# IPU2_UNICACHE_SCTM register map
Vendor: Texas Instruments
Peripheral module from a debugger description file (folder DRA74xP_75xP_76xP_77xP).
Registers are 32-bit, access per field, reset 0x0 unless marked. A register's access mark holds for its fields unless they carry their own. Offsets are as the file gives them; lines under a group give offsets from that group; [hi:lo] are bit positions; {n}, {i} and the like mark numbered series; 'fields as' and 'values as' point back to an identical list; <NAME> marks a mode.

## IPU2_UNICACHE_SCTM
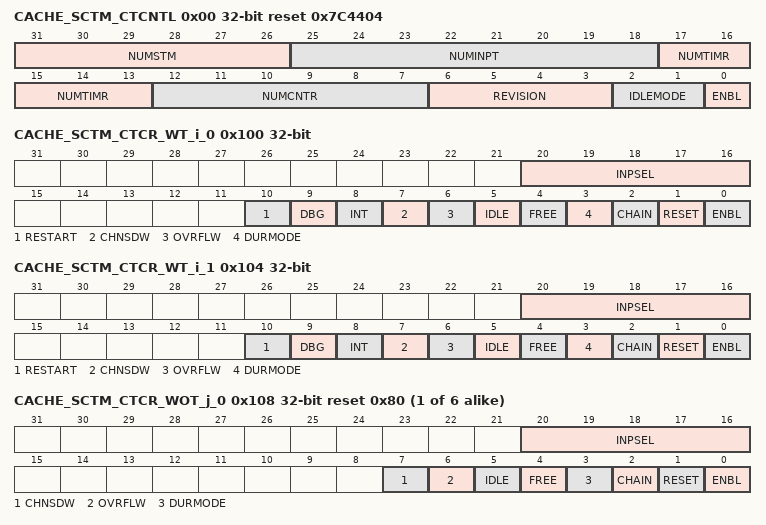
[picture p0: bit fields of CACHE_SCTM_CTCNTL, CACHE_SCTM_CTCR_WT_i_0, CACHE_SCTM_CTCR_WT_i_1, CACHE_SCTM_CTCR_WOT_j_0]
0x00 CACHE_SCTM_CTCNTL reset 0x7C4404 (reset mask 0xFFFFFF87)
  [31:26] NUMSTM ro — Number of timers that can export via STM
  [25:18] NUMINPT ro — Number of event input signals
  [17:13] NUMTIMR ro — Number of timers in the module
  [12:7] NUMCNTR ro — Number of counters in the module
  [6:3] REVISION ro — Revision ID of SCTM
  [2:1] IDLEMODE rw — Idle mode control
    0=Force_Idle_mode; 1=SCTM_1 (Ths SCTM will acknoledge the idle request, but never transition to the idle state); 2=SCTM_2 (Ths SCTM uses the smart idle protocol. This is the default mode); 3=SCTM_3 (Since the SCTM does not support internal wakeup, this mode is identical to smart_idle)
  [0] ENBL rw — SCTM global enable
    0=This module is disabled. Only the configuration interface is functional. All other logic is reset; 1=The module is enabled and individual counter/timers can be configured
0x40 CACHE_SCTM_TINTVLR_i_0 rw — These registers contain the interval match value for the corresponding timers in the SCTM
  [31:0] INTERVAL — Interval match value for the timers in the SCTM
0x44 CACHE_SCTM_TINTVLR_i_1 rw — These registers contain the interval match value for the corresponding timers in the SCTM
  [31:0] INTERVAL — Interval match value for the timers in the SCTM
0x7C CACHE_SCTM_CTDBGNUM ro — Counter Timer Number Debug Event Register
  [2:0] NUMEVT — Number of input selectors for debug events
0xF0 CACHE_SCTM_CTGNBL — These registers provide for simultaneous enable/disable of 32 counters
  [7:0] ENABLE rw — The counter enable bit field
0xF8 CACHE_SCTM_CTGRST — These registers provide for simultaneous reset of 32 counters
  [7:0] RESET rw — The counter reset bit field
0x100 CACHE_SCTM_CTCR_WT_i_0 — These registers contain the control and status settings for a single counter in the module. There will be a CTCR for every counter in the module (WT: with timer)
  [20:16] INPSEL rw — Counter Timer input selection1-31: Index of event input signal selected .
    0=Constantly asserted input that results in a free-running counter/timer
  [10] RESTART rw — Restart the timer after an interval match
    0=The timer stops after the first interval match. It must be manually reset by software before it starts counting again (run-once timer mode).; 1=The timer immediately resets to 0 and begins incrementing again based on the current input configuration (restart timer mode)
  [9] DBG rw — Signal debug logic on interval match
    0=No_debug_event_is_generated; 1=Upon interval match, generates a debug event on the corresponding debug output event signal
  [8] INT rw — Generate interrupt on interval match
    0=No_interrupt_is_generated; 1=Upon interval match, generates an interrupt on the corresponding interrupt output event signal
  [7] CHNSDW ro — Counter has a shadow register for chain reads.
    0=The read of the corresponding counter register returns the current value; 1=Read of the high-order counter register, simultaneously loads the current value of the 32 LSBs into a shadow register. The read of the counter register that corresponds to this counter returns the value of the shadow register. This is applicable only when the counter is chained.
  [6] OVRFLW ro — Counter has wrapped since it was last read
    0=The counter has not wrapped since the last read; 1=The counter has wrapped since the last read
  [5] IDLE rw — Counter ignores processor IDLE state
    0=The counter does not increment during IDLE state; 1=IDLE_IDLEMODE_1 (The counter continues to function during IDLE state; applicable if IDLEMODE = 1.)
  [4] FREE rw — Counter ignores processor debug halt state
    0=The counter does not increment (decrement) during the debug halt state; 1=The counter continues to function during debug halt state
  [3] DURMODE rw — Counter is in duration or occurrence mode
    0=The counter operates in event mode. The counter increments by 1 each time a rising edge is seen on the designated input event signal.; 1=The counter operates in duration mode. The counter increments every time a clock cycle is seen and the corresponding input event signal is asserted.
  [2] CHAIN rw — Counter is chained to an adjacent counter
    0=The_counter_is_not_chained
  [1] RESET rw — Counter reset control
    0=No_effect; 1=OVERFLW_1 (The corresponding counter is reset to the initial value and the OVERFLW bit is cleared. It continues to function if it is still enabled.)
  [0] ENBL rw — Counter enable control
    0=The_counter_does_not_increment; 1=The_counter_increments_as_configured
0x104 CACHE_SCTM_CTCR_WT_i_1 — These registers contain the control and status settings for a single counter in the module. There will be a CTCR for every counter in the module (WT: with timer)
  fields as CACHE_SCTM_CTCR_WT_i_0
{0x108+4i} CACHE_SCTM_CTCR_WOT_j_{i} reset 0x80 (i=0..5) — These registers contain the control and status settings for a single counter in the module. There will be a CTCR for every counter in the module (WOT: without timer)
  [20:16] INPSEL rw — Counter input selection1–31: Index of event input signal selected .
    0=Constant low signal on the output interface
  [7] CHNSDW ro — Counter has a shadow register for chain reads.
    values as CACHE_SCTM_CTCR_WT_i_0.CHNSDW
  [6] OVRFLW ro — Counter has wrapped since it was last read
    values as CACHE_SCTM_CTCR_WT_i_0.OVRFLW
  [5] IDLE rw — Counter ignores processor IDLE state
    values as CACHE_SCTM_CTCR_WT_i_0.IDLE
  [4] FREE rw — Counter ignores processor debug halt state
    values as CACHE_SCTM_CTCR_WT_i_0.FREE
  [3] DURMODE rw — Counter is in duration or occurrence mode
    values as CACHE_SCTM_CTCR_WT_i_0.DURMODE
  [2] CHAIN rw — Counter is chained to an adjacent counter
    0=The_counter_is_not_chained; 1=The_counter_is_chained_to_its_partner
  [1] RESET rw — Counter reset control
    values as CACHE_SCTM_CTCR_WT_i_0.RESET
  [0] ENBL rw — Counter enable control
    values as CACHE_SCTM_CTCR_WT_i_0.ENBL
{0x180+4i} CACHE_SCTM_CTCNTR_k_{i} ro (i=0..7) — These registers contain the value of an individual counter in the module. There will be a CTCNTR for every counter in the module
  [31:0] COUNT — Counter value
